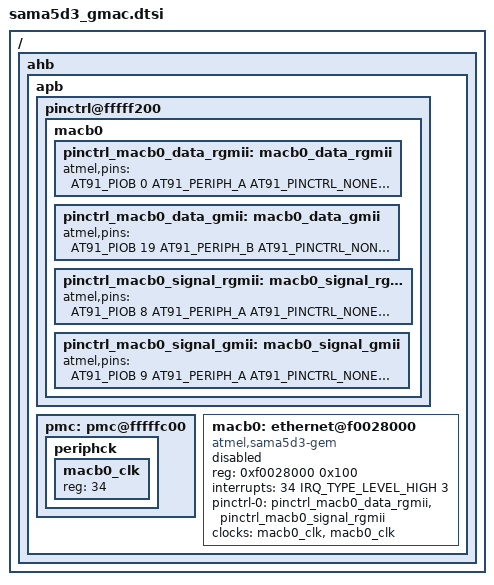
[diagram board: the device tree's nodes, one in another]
/*
 * sama5d3_gmac.dtsi - Device Tree Include file for SAMA5D3 SoC with
 * Gigabit Ethernet.
 *
 * Copyright (C) 2013 Boris BREZILLON <b.brezillon@overkiz.com>
 *
 * Licensed under GPLv2.
 */

#include <dt-bindings/pinctrl/at91.h>
#include <dt-bindings/interrupt-controller/irq.h>

/ {
	ahb {
		apb {
			pinctrl@fffff200 {
				macb0 {
					pinctrl_macb0_data_rgmii: macb0_data_rgmii {
						atmel,pins =
							<AT91_PIOB 0 AT91_PERIPH_A AT91_PINCTRL_NONE	/* PB0 periph A GTX0, conflicts with PWMH0 */
							 AT91_PIOB 1 AT91_PERIPH_A AT91_PINCTRL_NONE	/* PB1 periph A GTX1, conflicts with PWML0 */
							 AT91_PIOB 2 AT91_PERIPH_A AT91_PINCTRL_NONE	/* PB2 periph A GTX2, conflicts with TK1 */
							 AT91_PIOB 3 AT91_PERIPH_A AT91_PINCTRL_NONE	/* PB3 periph A GTX3, conflicts with TF1 */
							 AT91_PIOB 4 AT91_PERIPH_A AT91_PINCTRL_NONE	/* PB4 periph A GRX0, conflicts with PWMH1 */
							 AT91_PIOB 5 AT91_PERIPH_A AT91_PINCTRL_NONE	/* PB5 periph A GRX1, conflicts with PWML1 */
							 AT91_PIOB 6 AT91_PERIPH_A AT91_PINCTRL_NONE	/* PB6 periph A GRX2, conflicts with TD1 */
							 AT91_PIOB 7 AT91_PERIPH_A AT91_PINCTRL_NONE>;	/* PB7 periph A GRX3, conflicts with RK1 */
					};
					pinctrl_macb0_data_gmii: macb0_data_gmii {
						atmel,pins =
							<AT91_PIOB 19 AT91_PERIPH_B AT91_PINCTRL_NONE	/* PB19 periph B GTX4, conflicts with MCI1_CDA */
							 AT91_PIOB 20 AT91_PERIPH_B AT91_PINCTRL_NONE	/* PB20 periph B GTX5, conflicts with MCI1_DA0 */
							 AT91_PIOB 21 AT91_PERIPH_B AT91_PINCTRL_NONE	/* PB21 periph B GTX6, conflicts with MCI1_DA1 */
							 AT91_PIOB 22 AT91_PERIPH_B AT91_PINCTRL_NONE	/* PB22 periph B GTX7, conflicts with MCI1_DA2 */
							 AT91_PIOB 23 AT91_PERIPH_B AT91_PINCTRL_NONE	/* PB23 periph B GRX4, conflicts with MCI1_DA3 */
							 AT91_PIOB 24 AT91_PERIPH_B AT91_PINCTRL_NONE	/* PB24 periph B GRX5, conflicts with MCI1_CK */
							 AT91_PIOB 25 AT91_PERIPH_B AT91_PINCTRL_NONE	/* PB25 periph B GRX6, conflicts with SCK1 */
							 AT91_PIOB 26 AT91_PERIPH_B AT91_PINCTRL_NONE>;	/* PB26 periph B GRX7, conflicts with CTS1 */
					};
					pinctrl_macb0_signal_rgmii: macb0_signal_rgmii {
						atmel,pins =
							<AT91_PIOB 8 AT91_PERIPH_A AT91_PINCTRL_NONE	/* PB8 periph A GTXCK, conflicts with PWMH2 */
							 AT91_PIOB 9 AT91_PERIPH_A AT91_PINCTRL_NONE	/* PB9 periph A GTXEN, conflicts with PWML2 */
							 AT91_PIOB 11 AT91_PERIPH_A AT91_PINCTRL_NONE	/* PB11 periph A GRXCK, conflicts with RD1 */
							 AT91_PIOB 13 AT91_PERIPH_A AT91_PINCTRL_NONE	/* PB13 periph A GRXER, conflicts with PWML3 */
							 AT91_PIOB 16 AT91_PERIPH_A AT91_PINCTRL_NONE	/* PB16 periph A GMDC */
							 AT91_PIOB 17 AT91_PERIPH_A AT91_PINCTRL_NONE	/* PB17 periph A GMDIO */
							 AT91_PIOB 18 AT91_PERIPH_A AT91_PINCTRL_NONE>;	/* PB18 periph A G125CK */
					};
					pinctrl_macb0_signal_gmii: macb0_signal_gmii {
						atmel,pins =
							<AT91_PIOB 9 AT91_PERIPH_A AT91_PINCTRL_NONE	/* PB9 periph A GTXEN, conflicts with PWML2 */
							 AT91_PIOB 10 AT91_PERIPH_A AT91_PINCTRL_NONE	/* PB10 periph A GTXER, conflicts with RF1 */
							 AT91_PIOB 11 AT91_PERIPH_A AT91_PINCTRL_NONE	/* PB11 periph A GRXCK, conflicts with RD1 */
							 AT91_PIOB 12 AT91_PERIPH_A AT91_PINCTRL_NONE	/* PB12 periph A GRXDV, conflicts with PWMH3 */
							 AT91_PIOB 13 AT91_PERIPH_A AT91_PINCTRL_NONE	/* PB13 periph A GRXER, conflicts with PWML3 */
							 AT91_PIOB 14 AT91_PERIPH_A AT91_PINCTRL_NONE	/* PB14 periph A GCRS, conflicts with CANRX1 */
							 AT91_PIOB 15 AT91_PERIPH_A AT91_PINCTRL_NONE	/* PB15 periph A GCOL, conflicts with CANTX1 */
							 AT91_PIOB 16 AT91_PERIPH_A AT91_PINCTRL_NONE	/* PB16 periph A GMDC */
							 AT91_PIOB 17 AT91_PERIPH_A AT91_PINCTRL_NONE	/* PB17 periph A GMDIO */
							 AT91_PIOB 27 AT91_PERIPH_B AT91_PINCTRL_NONE>;	/* PB27 periph B G125CKO */
					};

				};
			};

			pmc: pmc@fffffc00 {
				periphck {
					macb0_clk: macb0_clk {
						#clock-cells = <0>;
						reg = <34>;
					};
				};
			};

			macb0: ethernet@f0028000 {
				compatible = "atmel,sama5d3-gem";
				reg = <0xf0028000 0x100>;
				interrupts = <34 IRQ_TYPE_LEVEL_HIGH 3>;
				pinctrl-names = "default";
				pinctrl-0 = <&pinctrl_macb0_data_rgmii &pinctrl_macb0_signal_rgmii>;
				clocks = <&macb0_clk>, <&macb0_clk>;
				clock-names = "hclk", "pclk";
				status = "disabled";
			};
		};
	};
};
